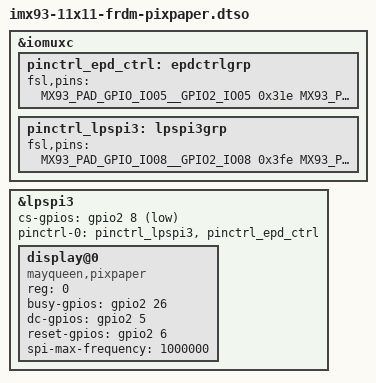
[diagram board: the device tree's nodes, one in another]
// SPDX-License-Identifier: GPL-2.0
/*
 * Device Tree Overlay for Mayqueen (Open-EP Community) pixpaper display
 * support on NXP FRDM i.MX 93 Development Board
 *
 * Copyright (C) 2026 Wig Cheng <onlywig@gmail.com>
 */

#include <dt-bindings/gpio/gpio.h>
#include "imx93-pinfunc.h"

/dts-v1/;
/plugin/;

&iomuxc {
	pinctrl_epd_ctrl: epdctrlgrp {
		fsl,pins = <
			MX93_PAD_GPIO_IO05__GPIO2_IO05		0x31e /* DC pin */
			MX93_PAD_GPIO_IO06__GPIO2_IO06		0x31e /* RESET pin */
			MX93_PAD_GPIO_IO26__GPIO2_IO26		0x31e /* BUSY pin */
		>;
	};

	pinctrl_lpspi3: lpspi3grp {
		fsl,pins = <
			MX93_PAD_GPIO_IO08__GPIO2_IO08		0x3fe /* SPI3 CE0 */
			MX93_PAD_GPIO_IO09__LPSPI3_SIN		0x3fe /* SPI3 MISO */
			MX93_PAD_GPIO_IO10__LPSPI3_SOUT		0x3fe /* SPI3 MOSI */
			MX93_PAD_GPIO_IO11__LPSPI3_SCK		0x3fe /* SPI3 CLK */
		>;
	};
};

&lpspi3 {
	#address-cells = <1>;
	#size-cells = <0>;
	cs-gpios = <&gpio2 8 GPIO_ACTIVE_LOW>;
	pinctrl-0 = <&pinctrl_lpspi3>, <&pinctrl_epd_ctrl>;
	pinctrl-names = "default";
	status = "okay";

	display@0 {
		compatible = "mayqueen,pixpaper";
		reg = <0>;
		busy-gpios = <&gpio2 26 GPIO_ACTIVE_HIGH>;
		dc-gpios = <&gpio2 5 GPIO_ACTIVE_HIGH>;
		reset-gpios = <&gpio2 6 GPIO_ACTIVE_HIGH>;
		spi-max-frequency = <1000000>;
	};
};
